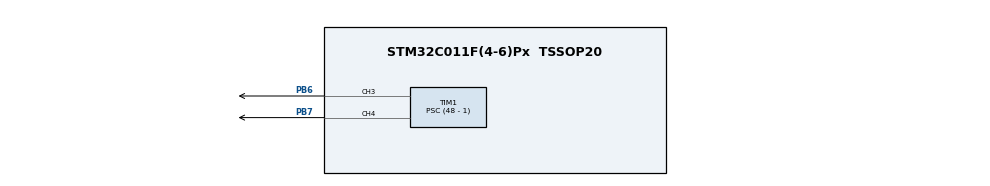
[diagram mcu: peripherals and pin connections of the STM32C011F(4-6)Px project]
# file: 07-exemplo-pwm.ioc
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Mcu.Family=STM32C0
Mcu.Name=STM32C011F(4-6)Px
Mcu.Package=TSSOP20
PA13.Mode=Serial_Wire
PA13.Signal=DEBUG_SWDIO
PA14-BOOT0.Mode=Serial_Wire
PA14-BOOT0.Signal=DEBUG_SWCLK
PB6.Signal=S_TIM1_CH3
PB7.Signal=S_TIM1_CH4
ProjectManager.HeapSize=0x200
ProjectManager.StackSize=0x400
ProjectManager.TargetToolchain=STM32CubeIDE
RCC.ADCFreq_Value=48000000
RCC.AHBFreq_Value=48000000
RCC.CortexFreq_Value=48000000
RCC.EXTERNAL_CLOCK_VALUE=12288000
RCC.HCLKFreq_Value=48000000
RCC.HSE_VALUE=8000000
RCC.HSISYSCLKDivider=RCC_HSI_DIV1
RCC.HSI_VALUE=48000000
RCC.LSE_VALUE=32768
RCC.SYSCLKFreq_VALUE=48000000
SH.S_TIM1_CH3.0=TIM1_CH3,PWM Generation3 CH3
SH.S_TIM1_CH4.0=TIM1_CH4,PWM Generation4 CH4
TIM1.Channel-PWM\ Generation3\ CH3=TIM_CHANNEL_3
TIM1.Channel-PWM\ Generation4\ CH4=TIM_CHANNEL_4
TIM1.Period=(1000 - 0)
TIM1.Prescaler=(48 - 1)
TIM1.Pulse-PWM\ Generation3\ CH3=0
TIM1.Pulse-PWM\ Generation4\ CH4=0
VP_TIM1_VS_ClockSourceINT.Mode=Internal
board=custom

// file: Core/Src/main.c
/* USER CODE BEGIN Header */
/**
  ******************************************************************************
  * @file           : main.c
  * @brief          : Main program body
  ******************************************************************************
  * @attention
  *
  * Copyright (c) 2023 STMicroelectronics.
  * All rights reserved.
  *
  * This software is licensed under terms that can be found in the LICENSE file
  * in the root directory of this software component.
  * If no LICENSE file comes with this software, it is provided AS-IS.
  *
  ******************************************************************************
  */
/* USER CODE END Header */
#include "main.h"
#include "tim.h"
#include "gpio.h"

void SystemClock_Config(void);

int main(void)
{
  /* USER CODE BEGIN 1 */

	uint16_t LED1_pulse, LED2_pulse;	// Variáveis para armazenar larguras de pulsos para LED1 (PB6, TIM1CH3) e LED2 (PB7, TIM1CH4)

	uint16_t i;							// Variável auxiliar para contagens

  /* USER CODE END 1 */

  /* MCU Configuration--------------------------------------------------------*/

  /* Reset of all peripherals, Initializes the Flash interface and the Systick. */
  HAL_Init();

  /* Configure the system clock */
  SystemClock_Config();

  /* Initialize all configured peripherals */
  MX_GPIO_Init();
  MX_TIM1_Init();
  /* USER CODE BEGIN 2 */

  HAL_TIM_PWM_Start(&htim1, TIM_CHANNEL_3);	// Inicia Timer 1 para geração de PWM no canais 3 (PB6, LED1)
  HAL_TIM_PWM_Start(&htim1, TIM_CHANNEL_4);	// Inicia Timer 1 para geração de PWM no canais 4 (PB7, LED2)

  // PWM configurado para largura de pulso de 0 a 1000

  /* USER CODE END 2 */

  /* Infinite loop */
  /* USER CODE BEGIN WHILE */
  while (1)
  {
	for (i = 0; i<1000; i++)
	{
		LED1_pulse = i;				// Aumenta gradualmente largura de pulso no LED1
		LED2_pulse = 1000 - i;;		// Diminui gradualmente largura de pulso no LED2

		__HAL_TIM_SET_COMPARE(&htim1, TIM_CHANNEL_3, LED1_pulse);	// Atualiza largura de pulso no LED1
		__HAL_TIM_SET_COMPARE(&htim1, TIM_CHANNEL_4, LED2_pulse);	// Atualiza largura de pulso no LED2

		HAL_Delay(1);				// Delay de 1ms
	}

	for (i = 1000; i>0; i--)		// Repete algoritmo anterior, porém de maneira inversa
	{
		LED1_pulse = i;
		LED2_pulse = 1000 - i;

		__HAL_TIM_SET_COMPARE(&htim1, TIM_CHANNEL_3, LED1_pulse);
		__HAL_TIM_SET_COMPARE(&htim1, TIM_CHANNEL_4, LED2_pulse);

		HAL_Delay(1);
	}

    /* USER CODE END WHILE */

  }
}

void SystemClock_Config(void)
{
  RCC_OscInitTypeDef RCC_OscInitStruct = {0};
  RCC_ClkInitTypeDef RCC_ClkInitStruct = {0};

  /** Initializes the RCC Oscillators according to the specified parameters
  * in the RCC_OscInitTypeDef structure.
  */
  RCC_OscInitStruct.OscillatorType = RCC_OSCILLATORTYPE_HSI;
  RCC_OscInitStruct.HSIState = RCC_HSI_ON;
  RCC_OscInitStruct.HSIDiv = RCC_HSI_DIV1;
  RCC_OscInitStruct.HSICalibrationValue = RCC_HSICALIBRATION_DEFAULT;
  if (HAL_RCC_OscConfig(&RCC_OscInitStruct) != HAL_OK)
  {
    Error_Handler();
  }

  /** Initializes the CPU, AHB and APB buses clocks
  */
  RCC_ClkInitStruct.ClockType = RCC_CLOCKTYPE_HCLK|RCC_CLOCKTYPE_SYSCLK
                              |RCC_CLOCKTYPE_PCLK1;
  RCC_ClkInitStruct.SYSCLKSource = RCC_SYSCLKSOURCE_HSI;
  RCC_ClkInitStruct.SYSCLKDivider = RCC_SYSCLK_DIV1;
  RCC_ClkInitStruct.AHBCLKDivider = RCC_HCLK_DIV1;
  RCC_ClkInitStruct.APB1CLKDivider = RCC_APB1_DIV1;

  if (HAL_RCC_ClockConfig(&RCC_ClkInitStruct, FLASH_LATENCY_1) != HAL_OK)
  {
    Error_Handler();
  }
}

void Error_Handler(void)
{
  __disable_irq();
  while (1)
  {
  }
}
